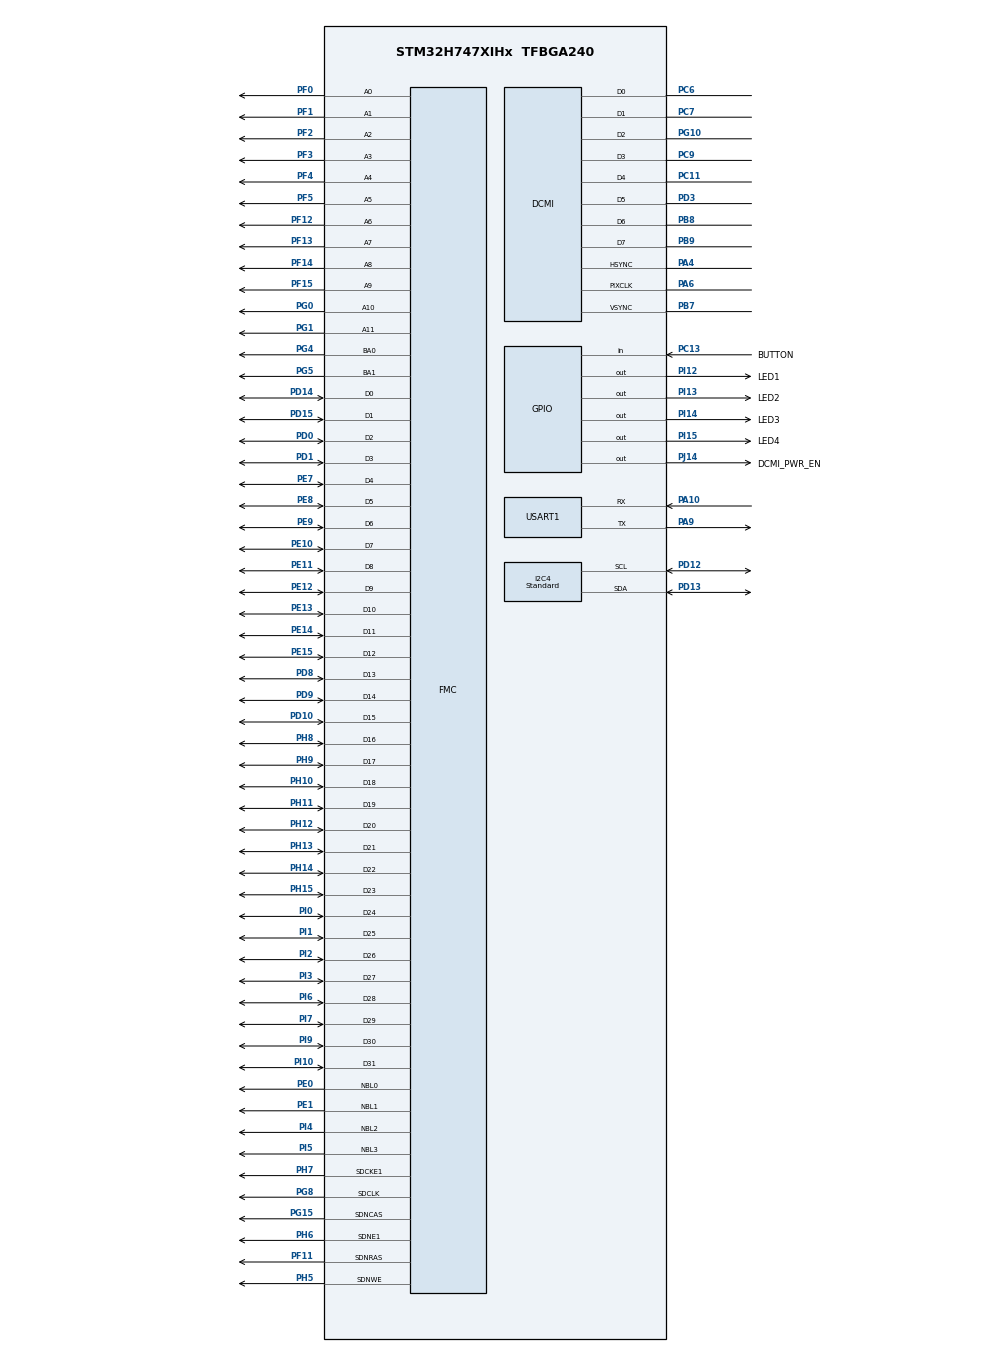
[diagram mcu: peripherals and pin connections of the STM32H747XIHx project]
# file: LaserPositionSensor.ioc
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CORTEX_M7.CPU_DCache=Disabled
CORTEX_M7.CPU_ICache=Enabled
CORTEX_M7.default_mode_Activation=0
CortexM4.IPs=BDMA,DMA,FATFS_M4\:I,FREERTOS_M4\:I,IWDG2\:I,MDMA,NVIC2\:I,RCC,USB_DEVICE_M4\:I,USB_HOST_M4\:I,WWDG2\:I,ADC1\:I,TIM3\:I,DEBUG,PDM2PCM_M4\:I,PWR,RESMGR_UTILITY,SYS_M4\:I,CORTEX_M4\:I,OPENAMP_M4\:I,VREFBUF
CortexM7.IPs=BDMA\:I,DMA\:I,FATFS_M7\:I,FREERTOS_M7\:I,IWDG1\:I,MDMA\:I,NVIC1\:I,RCC\:I,USB_DEVICE_M7\:I,USB_HOST_M7\:I,WWDG1\:I,CORTEX_M7\:I,DEBUG\:I,PDM2PCM_M7\:I,PWR\:I,RESMGR_UTILITY\:I,SYS\:I,OPENAMP_M7\:I,VREFBUF\:I,DCMI\:I,USART1\:I,I2C4\:I,FMC\:I
CortexM7.Pins=PJ14,PC13,PI12,PI13,PI14,PI15
DCMI.HSPolarity=DCMI_HSPOLARITY_HIGH
DCMI.PCKPolarity=DCMI_PCKPOLARITY_RISING
DCMI.VSPolarity=DCMI_VSPOLARITY_HIGH
Dma.DCMI.0.Direction=DMA_PERIPH_TO_MEMORY
Dma.DCMI.0.EventEnable=DISABLE
Dma.DCMI.0.FIFOMode=DMA_FIFOMODE_ENABLE
Dma.DCMI.0.FIFOThreshold=DMA_FIFO_THRESHOLD_FULL
Dma.DCMI.0.Instance=DMA2_Stream1
Dma.DCMI.0.MemBurst=DMA_MBURST_INC4
Dma.DCMI.0.MemDataAlignment=DMA_MDATAALIGN_WORD
Dma.DCMI.0.MemInc=DMA_MINC_ENABLE
Dma.DCMI.0.Mode=DMA_NORMAL
Dma.DCMI.0.PeriphBurst=DMA_PBURST_SINGLE
Dma.DCMI.0.PeriphDataAlignment=DMA_PDATAALIGN_WORD
Dma.DCMI.0.PeriphInc=DMA_PINC_DISABLE
Dma.DCMI.0.Polarity=HAL_DMAMUX_REQ_GEN_RISING
Dma.DCMI.0.Priority=DMA_PRIORITY_VERY_HIGH
Dma.DCMI.0.RequestNumber=1
Dma.DCMI.0.SignalID=NONE
Dma.DCMI.0.SyncEnable=DISABLE
Dma.DCMI.0.SyncPolarity=HAL_DMAMUX_SYNC_NO_EVENT
Dma.DCMI.0.SyncRequestNumber=1
Dma.DCMI.0.SyncSignalID=NONE
Dma.Request0=DCMI
FMC.CASLatency2=FMC_SDRAM_CAS_LATENCY_3
FMC.ColumnBitsNumber2=FMC_SDRAM_COLUMN_BITS_NUM_9
FMC.ExitSelfRefreshDelay2=7
FMC.LoadToActiveDelay2=2
FMC.RCDDelay2=2
FMC.RPDelay2=2
FMC.ReadBurst2=FMC_SDRAM_RBURST_ENABLE
FMC.RowCycleDelay2=7
FMC.SDClockPeriod2=FMC_SDRAM_CLOCK_PERIOD_2
FMC.SelfRefreshTime2=4
FMC.WriteRecoveryTime2=3
I2C4.I2C_Speed_Mode=I2C_Standard
I2C4.Timing=0x10C0ECFF
Mcu.Family=STM32H7
Mcu.Name=STM32H747XIHx
Mcu.Package=TFBGA240
NVIC1.DCMI_IRQn=true\:4\:0\:true\:false\:true\:true\:true\:true
NVIC1.DMA2_Stream1_IRQn=true\:5\:0\:true\:false\:true\:false\:true\:true
NVIC1.PriorityGroup=NVIC_PRIORITYGROUP_4
NVIC2.PriorityGroup=NVIC_PRIORITYGROUP_4
PA10.Mode=Asynchronous
PA10.PinAttribute=CortexM7
PA10.Signal=USART1_RX
PA13\ (JTMS/SWDIO).GPIO_Label=SWDIO
PA13\ (JTMS/SWDIO).Mode=Serial_Wire
PA13\ (JTMS/SWDIO).PinAttribute=CortexM7
PA13\ (JTMS/SWDIO).Signal=DEBUG_JTMS-SWDIO
PA14\ (JTCK/SWCLK).GPIO_Label=SWCLK
PA14\ (JTCK/SWCLK).Mode=Serial_Wire
PA14\ (JTCK/SWCLK).PinAttribute=CortexM7
PA14\ (JTCK/SWCLK).Signal=DEBUG_JTCK-SWCLK
PA4.Mode=Slave_8_bits_External_Synchro
PA4.PinAttribute=CortexM7
PA4.Signal=DCMI_HSYNC
PA6.Mode=Slave_8_bits_External_Synchro
PA6.PinAttribute=CortexM7
PA6.Signal=DCMI_PIXCLK
PA9.Mode=Asynchronous
PA9.PinAttribute=CortexM7
PA9.Signal=USART1_TX
PB7.Mode=Slave_8_bits_External_Synchro
PB7.PinAttribute=CortexM7
PB7.Signal=DCMI_VSYNC
PB8.Mode=Slave_8_bits_External_Synchro
PB8.PinAttribute=CortexM7
PB8.Signal=DCMI_D6
PB9.Mode=Slave_8_bits_External_Synchro
PB9.PinAttribute=CortexM7
PB9.Signal=DCMI_D7
PC11.Mode=Slave_8_bits_External_Synchro
PC11.PinAttribute=CortexM7
PC11.Signal=DCMI_D4
PC13.GPIO_Label=BUTTON
PC13.PinAttribute=CortexM7
PC13.Signal=GPIO_Input
PC14-OSC32_IN\ (OSC32_IN).Mode=LSE-External-Oscillator
PC14-OSC32_IN\ (OSC32_IN).PinAttribute=CortexM7
PC14-OSC32_IN\ (OSC32_IN).Signal=RCC_OSC32_IN
PC15-OSC32_OUT\ (OSC32_OUT).Mode=LSE-External-Oscillator
PC15-OSC32_OUT\ (OSC32_OUT).PinAttribute=CortexM7
PC15-OSC32_OUT\ (OSC32_OUT).Signal=RCC_OSC32_OUT
PC6.Mode=Slave_8_bits_External_Synchro
PC6.PinAttribute=CortexM7
PC6.Signal=DCMI_D0
PC7.Mode=Slave_8_bits_External_Synchro
PC7.PinAttribute=CortexM7
PC7.Signal=DCMI_D1
PC9.Mode=Slave_8_bits_External_Synchro
PC9.PinAttribute=CortexM7
PC9.Signal=DCMI_D3
PD0.PinAttribute=CortexM7
PD0.Signal=FMC_D2_DA2
PD1.PinAttribute=CortexM7
PD1.Signal=FMC_D3_DA3
PD10.PinAttribute=CortexM7
PD10.Signal=FMC_D15_DA15
PD12.Mode=I2C
PD12.PinAttribute=CortexM7
PD12.Signal=I2C4_SCL
PD13.Mode=I2C
PD13.PinAttribute=CortexM7
PD13.Signal=I2C4_SDA
PD14.PinAttribute=CortexM7
PD14.Signal=FMC_D0_DA0
PD15.PinAttribute=CortexM7
PD15.Signal=FMC_D1_DA1
PD3.Mode=Slave_8_bits_External_Synchro
PD3.PinAttribute=CortexM7
PD3.Signal=DCMI_D5
PD8.PinAttribute=CortexM7
PD8.Signal=FMC_D13_DA13
PD9.PinAttribute=CortexM7
PD9.Signal=FMC_D14_DA14
PE0.PinAttribute=CortexM7
PE0.Signal=FMC_NBL0
PE1.PinAttribute=CortexM7
PE1.Signal=FMC_NBL1
PE10.PinAttribute=CortexM7
PE10.Signal=FMC_D7_DA7
PE11.PinAttribute=CortexM7
PE11.Signal=FMC_D8_DA8
PE12.PinAttribute=CortexM7
PE12.Signal=FMC_D9_DA9
PE13.PinAttribute=CortexM7
PE13.Signal=FMC_D10_DA10
PE14.PinAttribute=CortexM7
PE14.Signal=FMC_D11_DA11
PE15.PinAttribute=CortexM7
PE15.Signal=FMC_D12_DA12
PE7.PinAttribute=CortexM7
PE7.Signal=FMC_D4_DA4
PE8.PinAttribute=CortexM7
PE8.Signal=FMC_D5_DA5
PE9.PinAttribute=CortexM7
PE9.Signal=FMC_D6_DA6
PF0.PinAttribute=CortexM7
PF0.Signal=FMC_A0
PF1.PinAttribute=CortexM7
PF1.Signal=FMC_A1
PF11.PinAttribute=CortexM7
PF11.Signal=FMC_SDNRAS
PF12.PinAttribute=CortexM7
PF12.Signal=FMC_A6
PF13.PinAttribute=CortexM7
PF13.Signal=FMC_A7
PF14.PinAttribute=CortexM7
PF14.Signal=FMC_A8
PF15.PinAttribute=CortexM7
PF15.Signal=FMC_A9
PF2.PinAttribute=CortexM7
PF2.Signal=FMC_A2
PF3.PinAttribute=CortexM7
PF3.Signal=FMC_A3
PF4.PinAttribute=CortexM7
PF4.Signal=FMC_A4
PF5.PinAttribute=CortexM7
PF5.Signal=FMC_A5
PG0.PinAttribute=CortexM7
PG0.Signal=FMC_A10
PG1.PinAttribute=CortexM7
PG1.Signal=FMC_A11
PG10.Mode=Slave_8_bits_External_Synchro
PG10.PinAttribute=CortexM7
PG10.Signal=DCMI_D2
PG15.PinAttribute=CortexM7
PG15.Signal=FMC_SDNCAS
PG2.PinAttribute=CortexM7
PG2.Signal=FMC_A12
PG4.PinAttribute=CortexM7
PG4.Signal=FMC_A14_BA0
PG5.PinAttribute=CortexM7
PG5.Signal=FMC_A15_BA1
PG8.PinAttribute=CortexM7
PG8.Signal=FMC_SDCLK
PH0-OSC_IN\ (PH0).Mode=HSE-External-Oscillator
PH0-OSC_IN\ (PH0).PinAttribute=CortexM7
PH0-OSC_IN\ (PH0).Signal=RCC_OSC_IN
PH1-OSC_OUT\ (PH1).Mode=HSE-External-Oscillator
PH1-OSC_OUT\ (PH1).PinAttribute=CortexM7
PH1-OSC_OUT\ (PH1).Signal=RCC_OSC_OUT
PH10.PinAttribute=CortexM7
PH10.Signal=FMC_D18
PH11.PinAttribute=CortexM7
PH11.Signal=FMC_D19
PH12.PinAttribute=CortexM7
PH12.Signal=FMC_D20
PH13.PinAttribute=CortexM7
PH13.Signal=FMC_D21
PH14.PinAttribute=CortexM7
PH14.Signal=FMC_D22
PH15.PinAttribute=CortexM7
PH15.Signal=FMC_D23
PH5.PinAttribute=CortexM7
PH5.Signal=FMC_SDNWE
PH6.Mode=SdramChipSelect2_2
PH6.PinAttribute=CortexM7
PH6.Signal=FMC_SDNE1
PH7.Mode=SdramChipSelect2_2
PH7.PinAttribute=CortexM7
PH7.Signal=FMC_SDCKE1
PH8.PinAttribute=CortexM7
PH8.Signal=FMC_D16
PH9.PinAttribute=CortexM7
PH9.Signal=FMC_D17
PI0.PinAttribute=CortexM7
PI0.Signal=FMC_D24
PI1.PinAttribute=CortexM7
PI1.Signal=FMC_D25
PI10.PinAttribute=CortexM7
PI10.Signal=FMC_D31
PI12.GPIO_Label=LED1
PI12.PinAttribute=CortexM7
PI12.Signal=GPIO_Output
PI13.GPIO_Label=LED2
PI13.PinAttribute=CortexM7
PI13.Signal=GPIO_Output
PI14.GPIO_Label=LED3
PI14.PinAttribute=CortexM7
PI14.Signal=GPIO_Output
PI15.GPIO_Label=LED4
PI15.PinAttribute=CortexM7
PI15.Signal=GPIO_Output
PI2.PinAttribute=CortexM7
PI2.Signal=FMC_D26
PI3.PinAttribute=CortexM7
PI3.Signal=FMC_D27
PI4.PinAttribute=CortexM7
PI4.Signal=FMC_NBL2
PI5.PinAttribute=CortexM7
PI5.Signal=FMC_NBL3
PI6.PinAttribute=CortexM7
PI6.Signal=FMC_D28
PI7.PinAttribute=CortexM7
PI7.Signal=FMC_D29
PI9.PinAttribute=CortexM7
PI9.Signal=FMC_D30
PJ14.GPIO_Label=DCMI_PWR_EN
PJ14.PinAttribute=CortexM7
PJ14.Signal=GPIO_Output
ProjectManager.HeapSize=M4-0x200,M7-0x200
ProjectManager.StackSize=M4-0x400,M7-0x400
ProjectManager.TargetToolchain=STM32CubeIDE
RCC.ADCFreq_Value=29296875
RCC.APB1Freq_Value=100000000
RCC.APB2Freq_Value=100000000
RCC.APB3Freq_Value=100000000
RCC.APB4Freq_Value=100000000
RCC.CortexFreq_Value=400000000
RCC.D1PPRE=RCC_APB3_DIV2
RCC.D2PPRE1=RCC_APB1_DIV2
RCC.D2PPRE2=RCC_APB2_DIV2
RCC.D3PPRE=RCC_APB4_DIV2
RCC.DIVM1=2
RCC.DIVM2=4
RCC.DIVN1=64
RCC.DIVN2=9
RCC.HCLKFreq_Value=200000000
RCC.HPRE=RCC_HCLK_DIV2
RCC.PLL2FRACN=3072
RCC.PLLFRACN=0
RCC.PLLSourceVirtual=RCC_PLLSOURCE_HSE
RCC.PWR_Regulator_Voltage_Scale=PWR_REGULATOR_VOLTAGE_SCALE1
RCC.SYSCLKFreq_VALUE=400000000
RCC.SYSCLKSource=RCC_SYSCLKSOURCE_PLLCLK
RCC.SupplySource=PWR_DIRECT_SMPS_SUPPLY
RCC.USBFreq_Value=400000000
SH.FMC_A0.0=FMC_A0,12b-sda2
SH.FMC_A1.0=FMC_A1,12b-sda2
SH.FMC_A10.0=FMC_A10,12b-sda2
SH.FMC_A11.0=FMC_A11,12b-sda2
SH.FMC_A12.0=FMC_A12
SH.FMC_A14_BA0.0=FMC_BA0,FourSdramBanks2
SH.FMC_A15_BA1.0=FMC_BA1,FourSdramBanks2
SH.FMC_A2.0=FMC_A2,12b-sda2
SH.FMC_A3.0=FMC_A3,12b-sda2
SH.FMC_A4.0=FMC_A4,12b-sda2
SH.FMC_A5.0=FMC_A5,12b-sda2
SH.FMC_A6.0=FMC_A6,12b-sda2
SH.FMC_A7.0=FMC_A7,12b-sda2
SH.FMC_A8.0=FMC_A8,12b-sda2
SH.FMC_A9.0=FMC_A9,12b-sda2
SH.FMC_D0_DA0.0=FMC_D0,sd-32b-d2
SH.FMC_D10_DA10.0=FMC_D10,sd-32b-d2
SH.FMC_D11_DA11.0=FMC_D11,sd-32b-d2
SH.FMC_D12_DA12.0=FMC_D12,sd-32b-d2
SH.FMC_D13_DA13.0=FMC_D13,sd-32b-d2
SH.FMC_D14_DA14.0=FMC_D14,sd-32b-d2
SH.FMC_D15_DA15.0=FMC_D15,sd-32b-d2
SH.FMC_D16.0=FMC_D16,sd-32b-d2
SH.FMC_D17.0=FMC_D17,sd-32b-d2
SH.FMC_D18.0=FMC_D18,sd-32b-d2
SH.FMC_D19.0=FMC_D19,sd-32b-d2
SH.FMC_D1_DA1.0=FMC_D1,sd-32b-d2
SH.FMC_D20.0=FMC_D20,sd-32b-d2
SH.FMC_D21.0=FMC_D21,sd-32b-d2
SH.FMC_D22.0=FMC_D22,sd-32b-d2
SH.FMC_D23.0=FMC_D23,sd-32b-d2
SH.FMC_D24.0=FMC_D24,sd-32b-d2
SH.FMC_D25.0=FMC_D25,sd-32b-d2
SH.FMC_D26.0=FMC_D26,sd-32b-d2
SH.FMC_D27.0=FMC_D27,sd-32b-d2
SH.FMC_D28.0=FMC_D28,sd-32b-d2
SH.FMC_D29.0=FMC_D29,sd-32b-d2
SH.FMC_D2_DA2.0=FMC_D2,sd-32b-d2
SH.FMC_D30.0=FMC_D30,sd-32b-d2
SH.FMC_D31.0=FMC_D31,sd-32b-d2
SH.FMC_D3_DA3.0=FMC_D3,sd-32b-d2
SH.FMC_D4_DA4.0=FMC_D4,sd-32b-d2
SH.FMC_D5_DA5.0=FMC_D5,sd-32b-d2
SH.FMC_D6_DA6.0=FMC_D6,sd-32b-d2
SH.FMC_D7_DA7.0=FMC_D7,sd-32b-d2
SH.FMC_D8_DA8.0=FMC_D8,sd-32b-d2
SH.FMC_D9_DA9.0=FMC_D9,sd-32b-d2
SH.FMC_NBL0.0=FMC_NBL0,Sd4ByteEnable2
SH.FMC_NBL1.0=FMC_NBL1,Sd4ByteEnable2
SH.FMC_NBL2.0=FMC_NBL2,Sd4ByteEnable2
SH.FMC_NBL3.0=FMC_NBL3,Sd4ByteEnable2
SH.FMC_SDCLK.0=FMC_SDCLK,12b-sda2
SH.FMC_SDNCAS.0=FMC_SDNCAS,12b-sda2
SH.FMC_SDNRAS.0=FMC_SDNRAS,12b-sda2
SH.FMC_SDNWE.0=FMC_SDNWE,12b-sda2
USART1.VirtualMode-Asynchronous=VM_ASYNC
VP_SYS_M4_VS_Systick.Mode=SysTick
board=STM32H747I-DISCO

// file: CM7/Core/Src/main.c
/* USER CODE BEGIN Header */
/**
  ******************************************************************************
  * @file           : main.c
  * @brief          : Main program body
  ******************************************************************************
  * @attention
  *
  * Copyright (c) 2022 STMicroelectronics.
  * All rights reserved.
  *
  * This software is licensed under terms that can be found in the LICENSE file
  * in the root directory of this software component.
  * If no LICENSE file comes with this software, it is provided AS-IS.
  *
  ******************************************************************************
  */
/* USER CODE END Header */
#include "main.h"
#include "dcmi.h"
#include "dma.h"
#include "i2c.h"
#include "usart.h"
#include "gpio.h"
#include "fmc.h"

/* USER CODE BEGIN Includes */
#include <stdbool.h>

#include "printf.h"
#include "main.h"
#include "stm32h747i_discovery_sdram.h"

#include "LPS_ov5640.h"
#include "LPS_DCMI.h"
#include "LPS_communication.h"
/* USER CODE END Includes */

/* USER CODE BEGIN PD */

#ifndef HSEM_ID_0
#define HSEM_ID_0 (0U) /* HW semaphore 0*/
#endif

/* USER CODE END PD */

/* USER CODE BEGIN PV */
extern uint32_t active_buffer;

uint8_t cameraLineBuffer0[CAMERA_LINE_SIZE] __attribute__ ((aligned (32)));
uint8_t cameraLineBuffer1[CAMERA_LINE_SIZE] __attribute__ ((aligned (32)));

uint32_t line_weight_vertical[CAMERA_RES_X];
uint32_t line_weight_horizontal[CAMERA_RES_Y];

uint32_t line_number = 0;

bool process_line = false;

/* USER CODE END PV */

void SystemClock_Config(void);
/* USER CODE BEGIN PFP */

void _putchar(char character);
void HAL_DCMI_VsyncEventCallback(DCMI_HandleTypeDef *hdcmi);
void HAL_DCMI_LineEventCallback(DCMI_HandleTypeDef *hdcmi);

/* USER CODE END PFP */

/* USER CODE BEGIN 0 */
void _putchar(char character)
{
	HAL_UART_Transmit(&huart1, (uint8_t*)&character, 1, 10);
}

/* full frame was received */
void HAL_DCMI_VsyncEventCallback(DCMI_HandleTypeDef *hdcmi)
{
	line_number = 0;
}

/* single line was received */
void HAL_DCMI_LineEventCallback(DCMI_HandleTypeDef *hdcmi)
{

}

double calculateCOG(uint32_t *buffer, uint32_t buffer_size)
{
	double weight_sum = 0;
	double cog = 0;

	for (uint32_t i = 1; i < buffer_size + 1; i++)
	{
		cog += buffer[i-1] * i;
		weight_sum += buffer[i-1];
	}
	cog = cog / weight_sum;

	return cog;
}

/* USER CODE END 0 */

int main(void)
{
/* USER CODE BEGIN Boot_Mode_Sequence_0 */
  int32_t timeout;
/* USER CODE END Boot_Mode_Sequence_0 */

  /* Enable I-Cache---------------------------------------------------------*/
  SCB_EnableICache();

/* USER CODE BEGIN Boot_Mode_Sequence_1 */
  /* Wait until CPU2 boots and enters in stop mode or timeout*/
  timeout = 0xFFFF;
  while((__HAL_RCC_GET_FLAG(RCC_FLAG_D2CKRDY) != RESET) && (timeout-- > 0));
  if ( timeout < 0 )
  {
  Error_Handler();
  }
/* USER CODE END Boot_Mode_Sequence_1 */
  /* MCU Configuration--------------------------------------------------------*/

  /* Reset of all peripherals, Initializes the Flash interface and the Systick. */
  HAL_Init();

  /* Configure the system clock */
  SystemClock_Config();
/* USER CODE BEGIN Boot_Mode_Sequence_2 */
	/* When system initialization is finished, Cortex-M7 will release Cortex-M4 by means of
	HSEM notification */

	__HAL_RCC_HSEM_CLK_ENABLE(); /*HW semaphore Clock enable*/
	HAL_HSEM_FastTake(HSEM_ID_0);	/*Take HSEM */
	HAL_HSEM_Release(HSEM_ID_0,0);/*Release HSEM in order to notify the CPU2(CM4)*/
	/* wait until CPU2 wakes up from stop mode */
	timeout = 0xFFFF;
	while((__HAL_RCC_GET_FLAG(RCC_FLAG_D2CKRDY) == RESET) && (timeout-- > 0)){}
	if ( timeout < 0 )
	{
		Error_Handler();
	}
/* USER CODE END Boot_Mode_Sequence_2 */

  /* USER CODE BEGIN SysInit */
  MX_DMA_Init();
  /* USER CODE END SysInit */

  /* Initialize all configured peripherals */
  MX_GPIO_Init();
  MX_USART1_UART_Init();
  MX_DMA_Init();
  MX_I2C4_Init();
  MX_DCMI_Init();
  MX_FMC_Init();
  /* USER CODE BEGIN 2 */

  /* init peripherals from BSP */
  BSP_SDRAM_Init(0);

  /* init ov5640 camera with I2C */
  ov5640_init();
  ov5640_SetPixelFormat(LPS_COLOR_FORMAT);
  ov5640_setResolution(LPS_RESOLUTION);

  /* set camera to test mode */
  //ov5640_enableTestMode();

  /* disable auto exposure and set it to lower value */
  ov5640_disableAutoExposure();
  ov5640_setManualExposure(8, 0);

  /* start initial frame capture */
  HAL_Delay(10);
  DCMI_Start_DMA_line(&hdcmi, DCMI_MODE_SNAPSHOT);

  /* USER CODE END 2 */

  /* Infinite loop */
  /* USER CODE BEGIN WHILE */
	while (1)
	{
		#if CAMERA_BITS_PER_PX==(24)
		/* wait until data in one of the buffers is ready to be processed */
		if (process_line == true)
		{
			process_line = false; //reset flag that was set by DMA TC interrupt

			uint32_t line_sum = 0;

			/* if buffer 0 is accessed by DMA, do calculations on buffer 1 */
			if (active_buffer == 0)
			{
				/* delete channels G and B */
				for (uint32_t i = 0; i < CAMERA_LINE_SIZE; i+=3)
				{
					cameraLineBuffer1[i + 1] = 0;
					cameraLineBuffer1[i + 2] = 0;
				}

				/* delete noise values */
				for (uint32_t i = 0; i < CAMERA_LINE_SIZE; i++)
				{
					if (cameraLineBuffer1[i] < RGB888_THRESHOLD)
						cameraLineBuffer1[i] = 0;
				}

				/* calculate sum of all pixels */
				for (uint32_t i = 0; i < CAMERA_LINE_SIZE; i++)
				{
					/* horizontal */
					line_sum += cameraLineBuffer1[i];

					/* vertical */
					line_weight_vertical[i / (CAMERA_BITS_PER_PX / 8)] += cameraLineBuffer1[i];
				}
			}

			/* if buffer 1 is accessed by DMA, do calculations on buffer 0 */
			if (active_buffer == 1)
			{
				/* delete channels G and B */
				for (uint32_t i = 0; i < CAMERA_LINE_SIZE; i+=3)
				{
					cameraLineBuffer0[i + 1] = 0;
					cameraLineBuffer0[i + 2] = 0;
				}

				/* delete noise values */
				for (uint32_t i = 0; i < CAMERA_LINE_SIZE; i++)
				{
					if (cameraLineBuffer0[i] < RGB888_THRESHOLD)
						cameraLineBuffer0[i] = 0;
				}

				/* calculate sum of all pixels */
				for (uint32_t i = 0; i < CAMERA_LINE_SIZE; i++)
				{
					/* horizontal */
					line_sum += cameraLineBuffer0[i];

					/* vertical */
					line_weight_vertical[i / (CAMERA_BITS_PER_PX / 8)] += cameraLineBuffer0[i];
				}
			}

			/* save sum of the currently processed line */
			line_weight_horizontal[line_number] = line_sum;
			line_number++;
			#endif

		#if CAMERA_BITS_PER_PX==(16)
		/* wait until data in one of the buffers is ready to be processed */
		if (process_line == true)
		{
			process_line = false; //reset flag that was set by DMA TC interrupt

			uint32_t line_sum = 0;

			/* if buffer 0 is accessed by DMA, do calculations on buffer 1 */
			if (active_buffer == 0)
			{
				/* delete channels G and B */
				for (uint32_t i = 0; i < CAMERA_LINE_SIZE; i+=2)
				{
					cameraLineBuffer1[i] = 0;
					cameraLineBuffer1[i + 1] &= 0b11111000;
				}

				/* delete noise values */
				for (uint32_t i = 0; i < CAMERA_LINE_SIZE; i++)
				{
					if (cameraLineBuffer1[i] < RGB565_THRESHOLD)
						cameraLineBuffer1[i] = 0;
				}

				/* calculate sum of all pixels */
				for (uint32_t i = 0; i < CAMERA_LINE_SIZE; i++)
				{
					/* horizontal */
					line_sum += cameraLineBuffer1[i];

					/* vertical */
					line_weight_vertical[i / (CAMERA_BITS_PER_PX / 8)] += cameraLineBuffer1[i];
				}
			}

			/* if buffer 1 is accessed by DMA, do calculations on buffer 0 */
			if (active_buffer == 1)
			{
				/* delete channels G and B */
				for (uint32_t i = 0; i < CAMERA_LINE_SIZE; i+=2)
				{
					cameraLineBuffer0[i] = 0;
					cameraLineBuffer0[i + 1] &= 0b11111000;
				}

				/* delete noise values */
				for (uint32_t i = 0; i < CAMERA_LINE_SIZE; i++)
				{
					if (cameraLineBuffer0[i] < RGB565_THRESHOLD)
						cameraLineBuffer0[i] = 0;
				}

				/* calculate sum of all pixels */
				for (uint32_t i = 0; i < CAMERA_LINE_SIZE; i++)
				{
					/* horizontal */
					line_sum += cameraLineBuffer0[i];

					/* vertical */
					line_weight_vertical[i / (CAMERA_BITS_PER_PX / 8)] += cameraLineBuffer0[i];
				}
			}

			/* save sum of the currently processed line */
			line_weight_horizontal[line_number] = line_sum;
			line_number++;
			#endif

			/* if last line of the frame was taken, print results */
			if (line_number >= CAMERA_RES_Y)
			{
				printDataToMatlab(line_weight_horizontal, CAMERA_RES_Y, line_weight_vertical, CAMERA_RES_X);

				double cog_h = calculateCOG(line_weight_vertical, CAMERA_RES_X);
				double cog_v = calculateCOG(line_weight_horizontal, CAMERA_RES_Y);

				printCOGToMatlab(cog_h, cog_v);

				/* reset values in vertical sums buffer */
				for (uint32_t i = 0; i < CAMERA_LINE_SIZE; i++)
				{
					line_weight_vertical[i / (CAMERA_BITS_PER_PX / 8)] = 0;
				}

				/* start capturing next frame */
				DCMI_Start_DMA_line(&hdcmi, DCMI_MODE_SNAPSHOT);

			}
		}

    /* USER CODE END WHILE */

    }
}

void SystemClock_Config(void)
{
  RCC_OscInitTypeDef RCC_OscInitStruct = {0};
  RCC_ClkInitTypeDef RCC_ClkInitStruct = {0};

  /** Supply configuration update enable
  */
  HAL_PWREx_ConfigSupply(PWR_DIRECT_SMPS_SUPPLY);

  /** Configure the main internal regulator output voltage
  */
  __HAL_PWR_VOLTAGESCALING_CONFIG(PWR_REGULATOR_VOLTAGE_SCALE1);

  while(!__HAL_PWR_GET_FLAG(PWR_FLAG_VOSRDY)) {}

  /** Initializes the RCC Oscillators according to the specified parameters
  * in the RCC_OscInitTypeDef structure.
  */
  RCC_OscInitStruct.OscillatorType = RCC_OSCILLATORTYPE_HSE;
  RCC_OscInitStruct.HSEState = RCC_HSE_ON;
  RCC_OscInitStruct.PLL.PLLState = RCC_PLL_ON;
  RCC_OscInitStruct.PLL.PLLSource = RCC_PLLSOURCE_HSE;
  RCC_OscInitStruct.PLL.PLLM = 2;
  RCC_OscInitStruct.PLL.PLLN = 64;
  RCC_OscInitStruct.PLL.PLLP = 2;
  RCC_OscInitStruct.PLL.PLLQ = 2;
  RCC_OscInitStruct.PLL.PLLR = 2;
  RCC_OscInitStruct.PLL.PLLRGE = RCC_PLL1VCIRANGE_3;
  RCC_OscInitStruct.PLL.PLLVCOSEL = RCC_PLL1VCOWIDE;
  RCC_OscInitStruct.PLL.PLLFRACN = 0;
  if (HAL_RCC_OscConfig(&RCC_OscInitStruct) != HAL_OK)
  {
    Error_Handler();
  }

  /** Initializes the CPU, AHB and APB buses clocks
  */
  RCC_ClkInitStruct.ClockType = RCC_CLOCKTYPE_HCLK|RCC_CLOCKTYPE_SYSCLK
                              |RCC_CLOCKTYPE_PCLK1|RCC_CLOCKTYPE_PCLK2
                              |RCC_CLOCKTYPE_D3PCLK1|RCC_CLOCKTYPE_D1PCLK1;
  RCC_ClkInitStruct.SYSCLKSource = RCC_SYSCLKSOURCE_PLLCLK;
  RCC_ClkInitStruct.SYSCLKDivider = RCC_SYSCLK_DIV1;
  RCC_ClkInitStruct.AHBCLKDivider = RCC_HCLK_DIV2;
  RCC_ClkInitStruct.APB3CLKDivider = RCC_APB3_DIV2;
  RCC_ClkInitStruct.APB1CLKDivider = RCC_APB1_DIV2;
  RCC_ClkInitStruct.APB2CLKDivider = RCC_APB2_DIV2;
  RCC_ClkInitStruct.APB4CLKDivider = RCC_APB4_DIV2;

  if (HAL_RCC_ClockConfig(&RCC_ClkInitStruct, FLASH_LATENCY_2) != HAL_OK)
  {
    Error_Handler();
  }
}

void Error_Handler(void)
{
  __disable_irq();
  while (1)
  {
  }
}
